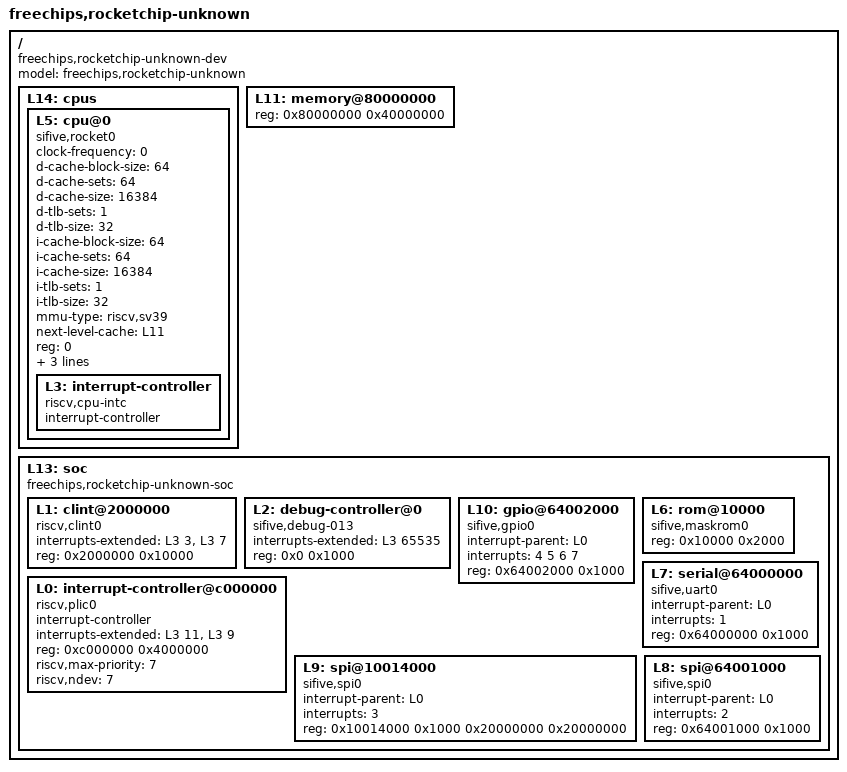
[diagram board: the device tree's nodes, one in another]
/dts-v1/;

/ {
	#address-cells = <1>;
	#size-cells = <1>;
	compatible = "freechips,rocketchip-unknown-dev";
	model = "freechips,rocketchip-unknown";
	L14: cpus {
		#address-cells = <1>;
		#size-cells = <0>;
		L5: cpu@0 {
			clock-frequency = <0>;
			compatible = "sifive,rocket0", "riscv";
			d-cache-block-size = <64>;
			d-cache-sets = <64>;
			d-cache-size = <16384>;
			d-tlb-sets = <1>;
			d-tlb-size = <32>;
			device_type = "cpu";
			i-cache-block-size = <64>;
			i-cache-sets = <64>;
			i-cache-size = <16384>;
			i-tlb-sets = <1>;
			i-tlb-size = <32>;
			mmu-type = "riscv,sv39";
			next-level-cache = <&L11>;
			reg = <0>;
			riscv,isa = "rv64imafdc";
			status = "okay";
			timebase-frequency = <1000000>;
			tlb-split;
			L3: interrupt-controller {
				#interrupt-cells = <1>;
				compatible = "riscv,cpu-intc";
				interrupt-controller;
			};
		};
	};
	L11: memory@80000000 {
		device_type = "memory";
		reg = <0x80000000 0x40000000>;
	};
	L13: soc {
		#address-cells = <1>;
		#size-cells = <1>;
		compatible = "freechips,rocketchip-unknown-soc", "simple-bus";
		ranges;
		L1: clint@2000000 {
			compatible = "riscv,clint0";
			interrupts-extended = <&L3 3 &L3 7>;
			reg = <0x2000000 0x10000>;
			reg-names = "control";
		};
		L2: debug-controller@0 {
			compatible = "sifive,debug-013", "riscv,debug-013";
			interrupts-extended = <&L3 65535>;
			reg = <0x0 0x1000>;
			reg-names = "control";
		};
		L10: gpio@64002000 {
			compatible = "sifive,gpio0";
			interrupt-parent = <&L0>;
			interrupts = <4 5 6 7>;
			reg = <0x64002000 0x1000>;
			reg-names = "control";
		};
		L0: interrupt-controller@c000000 {
			#interrupt-cells = <1>;
			compatible = "riscv,plic0";
			interrupt-controller;
			interrupts-extended = <&L3 11 &L3 9>;
			reg = <0xc000000 0x4000000>;
			reg-names = "control";
			riscv,max-priority = <7>;
			riscv,ndev = <7>;
		};
		L6: rom@10000 {
			compatible = "sifive,maskrom0";
			reg = <0x10000 0x2000>;
			reg-names = "mem";
		};
		L7: serial@64000000 {
			compatible = "sifive,uart0";
			interrupt-parent = <&L0>;
			interrupts = <1>;
			reg = <0x64000000 0x1000>;
			reg-names = "control";
		};
		L9: spi@10014000 {
			compatible = "sifive,spi0";
			interrupt-parent = <&L0>;
			interrupts = <3>;
			reg = <0x10014000 0x1000 0x20000000 0x20000000>;
			reg-names = "control", "mem";
		};
		L8: spi@64001000 {
			compatible = "sifive,spi0";
			interrupt-parent = <&L0>;
			interrupts = <2>;
			reg = <0x64001000 0x1000>;
			reg-names = "control";
		};
	};
};
